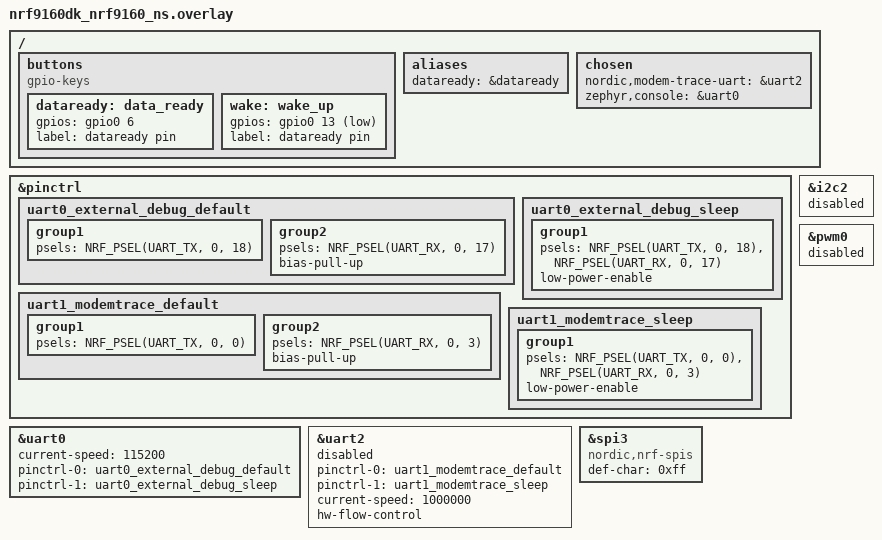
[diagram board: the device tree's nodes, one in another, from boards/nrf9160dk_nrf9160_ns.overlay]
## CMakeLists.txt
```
#
# Copyright (c) 2020 Nordic Semiconductor
#
# SPDX-License-Identifier: LicenseRef-Nordic-5-Clause
#

cmake_minimum_required(VERSION 3.20.0)

list(APPEND CONF_FILE prj.conf)

if (EXISTS prj.local.conf)
  list(APPEND CONF_FILE prj.local.conf)
endif()
if (CONFIG_RELEASE_BUILD)
  message("Doing a RELEASE build")
  list(APPEND CONF_FILE prj.release.conf)
endif()

find_package(Zephyr REQUIRED HINTS $ENV{ZEPHYR_BASE})
project(purina_d1_lte  VERSION 1.1.12)
zephyr_library_include_directories(src/include)




target_sources(app PRIVATE src/main.c)
target_sources(app PRIVATE src/wi.c)
target_sources(app PRIVATE src/status/status.c)
target_sources(app PRIVATE src/network/network.c)
target_sources(app PRIVATE src/zbus/zbus_msgs.c)
target_sources(app PRIVATE src/zbus/shutdown.c)
target_sources(app PRIVATE src/spi/spis_interface.c)
target_sources(app PRIVATE src/purina_iot/transport.c)
target_sources(app PRIVATE src/purina_iot/fota.c)
target_sources(app PRIVATE src/purina_iot/nrf91_upgrade.c)
add_subdirectory(src/gps)



zephyr_include_directories(src)
zephyr_include_directories(src/include)
zephyr_include_directories(src/spi)
zephyr_include_directories(src/zbus)
zephyr_include_directories(src/network)
zephyr_include_directories(src/status)
zephyr_include_directories(src/purina_iot)
zephyr_include_directories(../c_modules/modem/include)
zephyr_include_directories(src/gps)
target_include_directories(app PRIVATE ${ZEPHYR_BASE}/../nrf/ext/curl/include/)
target_include_directories(app PRIVATE ${ZEPHYR_BASE}/include/zephyr/posix/)
add_definitions(-DAPP_VERSION_MAJOR_CMAKE=${PROJECT_VERSION_MAJOR})
add_definitions(-DAPP_VERSION_MINOR_CMAKE=${PROJECT_VERSION_MINOR})
add_definitions(-DAPP_VERSION_PATCH_CMAKE=${PROJECT_VERSION_PATCH})



# Get the current Git commit hash
execute_process(
  COMMAND git rev-parse --short=6 HEAD
  WORKING_DIRECTORY ${CMAKE_SOURCE_DIR}
  OUTPUT_VARIABLE GIT_HASH
  OUTPUT_STRIP_TRAILING_WHITESPACE
)

# Check if the repository is dirty
execute_process(
  COMMAND git status --porcelain
  WORKING_DIRECTORY ${CMAKE_SOURCE_DIR}
  OUTPUT_VARIABLE GIT_DIRTY_STATUS
  OUTPUT_STRIP_TRAILING_WHITESPACE
)

# Append '-dirty' to the version string if the repository is dirty
if(NOT GIT_DIRTY_STATUS STREQUAL "")
  set(GIT_HASH "${GIT_HASH}-dirty")
endif()

add_definitions(-DGIT_HASH_CMAKE=\"${GIT_HASH}\")

# Get the build machine name
execute_process(
  COMMAND hostname
  OUTPUT_VARIABLE BUILD_MACHINE
  OUTPUT_STRIP_TRAILING_WHITESPACE
)

# Get the build date
string(TIMESTAMP BUILD_DATE "%Y-%m-%d %H:%M:%S")

# Pass the variables to the code
add_definitions(-DBUILD_MACHINE_CMAKE=\"${BUILD_MACHINE}\")
add_definitions(-DBUILD_DATE_CMAKE=\"${BUILD_DATE}\")
```

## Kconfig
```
#
# Copyright (c) 2020 Nordic Semiconductor ASA
#
# SPDX-License-Identifier: LicenseRef-Nordic-5-Clause
#

menu "Purina D1 LTE Settings"

config PURINA_D1_LTE_JSON_MESSAGE_SIZE_MAX
	int "Maximum size of JSON messages"
	default 5120
	help
	  Maximum size of JSON messages that are sent to AWS IoT.

config PURINA_D1_LTE_JSON_TOPIC_SIZE_MAX
	int "Maximum size of JSON topics"
	default 48
	help
	  Maximum size of JSON topics that are sent to AWS IoT.

config PURINA_D1_LTE_IOT_BROKER_HOST_NAME_SIZE_MAX
	int "Maximum size of AWS IoT broker host name"
	default 64
	help
	  Maximum size of AWS IoT broker host name.

config PURINA_D1_LTE_CLIENT_ID_SIZE_MAX
	int "Maximum size of client ID string"
	default 32
	help
	  Maximum size of string for client ID.

config PURINA_D1_LTE_CLIENT_MAX_SUBSCRIPTION_TOPICS
	int "Maximum num of subscription topics"
	default 10

config PURINA_D1_LTE_PUBLICATION_INTERVAL_SECONDS
	int "Interval in seconds that the app will publish uptime/info data"
	default 60
	help
	  Currently sends info to a topic $aws/things/{HW_id}/shadow/update/documents with things like versions, uptime, etc.

config PURINA_D1_LTE_CONNECTION_RETRY_TIMEOUT_SECONDS
	int "Number of seconds between each AWS IoT connection retry"
	default 30

config PURINA_D1_LTE_MQTT_RECONNECTION_TIMEOUT_SECONDS
	int "Reconnection timeout in seconds"
	default 10
	help
	  Time in between reconnection attempts to the MQTT broker.

config PURINA_D1_SPIS_LOG_LEVEL
	int "spi module log level"
	default 4

config PURINA_D1_SPIS_RX_BUFFER_SIZE
	int "spi module rx buffer size"
	default 5120
	help
	  The size of the SPI module's RX buffer. defaulted to 5120 to support Nick's 5k power testing.

config PURINA_D1_SPIS_TX_BUFFER_SIZE
	int "spi module tx buffer size"
	default 3072

config PURINA_D1_LTE_DOWNLOAD_URL_SIZE_MAX
	int "Maximum size of download URL"
	default 2096
	help
	  Maximum size of download URL.

config PURINA_D1_DISABLE_MODEM_ON_BOOT
	bool "pause the boot before the modem connects"
	default n

config PURINA_D1_REBOOT_ON_ERROR
	bool "reboot on error"
	default y

config PURINA_D1_LTE_LOG_LEVEL
	int "log level"
	default 4

config PURINA_D1_DOWNLOAD_SECURITY_TAG
	int "download security tag"
	default 123

config PURINA_D1_LTE_GNSS_SAMPLE_MODE_CONTINUOUS
	bool "GNSS sample mode continuous"
	default y

config PURINA_D1_LTE_CLIENT_ID_PREFIX
	string "Client ID prefix"
	default "dog-"

config PURINA_D1_LTE_PRINT_GPS_STATS
	bool "Print GPS stats"
	default n

config PURINA_D1_LTE_ENABLE_ZBUS_LOG_MESSAGES
	bool "Enable log messages sent over zbus then to the 5340 - using send_zbus_debug_info()"
	default y

config PURINA_D1_LTE_ZBUS_LOG_MESSAGE_LEVEL
	int "Zbus log message level - any message with a level less than or equal this will be sent over zbus"
	default 3

config GNSS_PRIORITY_ON_FIRST_FIX
	bool "GNSS priority on first fix"
	default y

config RELEASE_BUILD
    bool "Production Release"
    help
      Set to true to disable various developer features and to enable additonal security

config PURINA_D1_LTE_FOTA_CHUNK_SIZE_MAX
	int "Maximum size of FOTA chunk"
	default 1024
	help
	  Maximum size of FOTA chunk.

rsource "src/gps/Kconfig"

module = PURINA_D1_LTE
module-str = Purina D1 LTE
source "${ZEPHYR_BASE}/subsys/logging/Kconfig.template.log_config"

endmenu

menu "Zephyr Kernel"
source "Kconfig.zephyr"
endmenu
```

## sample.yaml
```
sample:
  name: Purina D1 LTE
tests:
  sample.net.aws_iot:
    tags: ci_build
    build_only: true
    build_on_all: true
    integration_platforms:
      - nrf9160dk_nrf9160_ns
    platform_allow:
      - nrf9160dk_nrf9160_ns
```

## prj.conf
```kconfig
#
# Copyright (c) 2020 Nordic Semiconductor ASA
#
# SPDX-License-Identifier: LicenseRef-Nordic-5-Clause
#

# General
CONFIG_LOG=y
CONFIG_LOG_BUFFER_SIZE=2048
CONFIG_HW_ID_LIBRARY=y
CONFIG_ASSERT=y
CONFIG_JSON_LIBRARY=y

# Heap and stacks
CONFIG_HEAP_MEM_POOL_SIZE=8192
CONFIG_MAIN_STACK_SIZE=4096
CONFIG_SYSTEM_WORKQUEUE_STACK_SIZE=4096

# Network
CONFIG_NETWORKING=y
CONFIG_NET_NATIVE=y
CONFIG_NET_IPV4=y
CONFIG_NET_CONNECTION_MANAGER=y

CONFIG_SMF=y
CONFIG_REBOOT=y

CONFIG_MQTT_HELPER=y
CONFIG_MQTT_HELPER_SEC_TAG=123
CONFIG_MODEM_KEY_MGMT=y 

CONFIG_MQTT_CLEAN_SESSION=y

# TLS
CONFIG_MQTT_LIB_TLS=y
CONFIG_MQTT_HELPER_PORT=8883
CONFIG_MQTT_KEEPALIVE=600
CONFIG_MQTT_HELPER_STACK_SIZE=4096

CONFIG_BOOTLOADER_MCUBOOT=y
CONFIG_MCUBOOT_IMG_MANAGER=y

CONFIG_SPI=n
CONFIG_NRFX_SPIS3=y

# Flash - Used in FOTA, settings and storage for P-GPS.
CONFIG_STREAM_FLASH=y
CONFIG_FLASH=y
CONFIG_FLASH_PAGE_LAYOUT=y
CONFIG_FLASH_MAP=y
CONFIG_FCB=y
CONFIG_SETTINGS=y
CONFIG_SETTINGS_FCB=y
CONFIG_MPU_ALLOW_FLASH_WRITE=y


# MCUBOOT
CONFIG_BOOTLOADER_MCUBOOT=y
CONFIG_IMG_MANAGER=y
CONFIG_MCUBOOT_IMG_MANAGER=y
CONFIG_IMG_ERASE_PROGRESSIVELY=y
CONFIG_SECURE_BOOT=y
CONFIG_BUILD_S1_VARIANT=y
CONFIG_PM_EXTERNAL_FLASH_MCUBOOT_SECONDARY=n

CONFIG_ZBUS=y
#CONFIG_ZBUS_RUNTIME_OBSERVERS=y

# # LTE Link Control
CONFIG_LTE_LINK_CONTROL=y
CONFIG_LTE_NETWORK_MODE_LTE_M_GPS=y
# Request eDRX from the network
CONFIG_LTE_EDRX_REQ=y
CONFIG_LTE_PSM_REQ=y
# PSM requested periodic TAU 1 hour, dafault is 00000011
CONFIG_LTE_PSM_REQ_RPTAU="10000010"
CONFIG_LTE_PSM_REQ_RAT="00001000"

# default is 1001
# 0100 is 61.44 seconds
# 0011 is 40.96 seconds
CONFIG_LTE_EDRX_REQ_VALUE_NBIOT="0100"
#default is 1001
CONFIG_LTE_EDRX_REQ_VALUE_LTE_M="0100"
CONFIG_LTE_PTW_VALUE_LTE_M="0011"
CONFIG_LTE_PTW_VALUE_NBIOT="0011"
CONFIG_LTE_LINK_CONTROL=y
CONFIG_PURINA_D1_LTE_GNSS_SAMPLE_MODE_CONTINUOUS=y

CONFIG_REBOOT=y
CONFIG_CJSON_LIB=y

CONFIG_MQTT_HELPER_PAYLOAD_BUFFER_LEN=3072

## debug/demo flags here
CONFIG_PURINA_D1_DISABLE_MODEM_ON_BOOT=n
CONFIG_PURINA_D1_REBOOT_ON_ERROR=n
CONFIG_PM_DEVICE=y
CONFIG_POWEROFF=y
CONFIG_MQTT_HELPER_LOG_LEVEL_DBG=y
CONFIG_NRF_MODEM_LIB_TRACE=n
CONFIG_PURINA_D1_LTE_LOG_LEVEL=4
# CONFIG_SHELL_CMD_BUFF_SIZE=255
# CONFIG_SHELL_CMDS_RESIZE=y
CONFIG_HTTP_PARSER=y
CONFIG_FOTA_DOWNLOAD_LOG_LEVEL_DBG=y
CONFIG_DFU_TARGET_MCUBOOT=y
CONFIG_DOWNLOAD_CLIENT=y
CONFIG_DOWNLOAD_CLIENT_STACK_SIZE=4096
CONFIG_DFU_TARGET=y
#debug
# CONFIG_MQTT_HELPER_STACK_SIZE=4096
# CONFIG_MAIN_STACK_SIZE=4096
# CONFIG_SYSTEM_WORKQUEUE_STACK_SIZE=2048

# handle te super long pre-signed FOTA urls
CONFIG_DOWNLOAD_CLIENT_MAX_FILENAME_SIZE=2048
CONFIG_DOWNLOAD_CLIENT_MAX_HOSTNAME_SIZE=256
CONFIG_FOTA_DOWNLOAD=y
CONFIG_FOTA_DOWNLOAD_FILE_NAME_LENGTH=2048
CONFIG_FOTA_DOWNLOAD_HOST_NAME_LENGTH=256
#CONFIG_MQTT_LOG_LEVEL_DBG=y

CONFIG_DK_LIBRARY=y
CONFIG_NET_TCP=y
CONFIG_MQTT_HELPER_RX_TX_BUFFER_SIZE=4096
CONFIG_FOTA_DOWNLOAD_PROGRESS_EVT=y

CONFIG_DEBUG_THREAD_INFO=y

# Enable nRF Cloud assistance for GNSS sample
CONFIG_PURINA_D1_LTE_ASSISTANCE_NRF_CLOUD=y

# P-GPS
CONFIG_NRF_CLOUD_PGPS=y
CONFIG_NRF_CLOUD_PGPS_REPLACEMENT_THRESHOLD=4

# Disable A-GNSS, comment this if you want to use both A-GNSS and P-GPS at the same time
#CONFIG_NRF_CLOUD_AGNSS=n


#CONFIG_SUPL_CLIENT_LIB=y

# Enable SUPL assistance for GNSS sample
CONFIG_PURINA_D1_LTE_ASSISTANCE_SUPL=n
# SUPL client library requires that the newlib C library is used
#CONFIG_NEWLIB_LIBC=y
#CONFIG_NEWLIB_LIBC_FLOAT_PRINTF=y
CONFIG_CBPRINTF_FP_SUPPORT=y

# LTE Link Control
CONFIG_LTE_LINK_CONTROL=y
CONFIG_LTE_NETWORK_MODE_LTE_M_GPS=y
# Request eDRX from the network



# CONFIG_PURINA_D1_LTE_ASSISTANCE_NRF_CLOUD=n
# Enable nRF Cloud assistance for GNSS sample
CONFIG_PURINA_D1_LTE_ASSISTANCE_NRF_CLOUD=y

# P-GPS
CONFIG_NRF_CLOUD_SEC_TAG=16842753
#CONFIG_NRF_CLOUD_CLIENT_ID_SRC_INTERNAL_UUID=y
CONFIG_NRF_CLOUD_CLIENT_ID_SRC_IMEI=y
CONFIG_PURINA_D1_LTE_CLIENT_ID_PREFIX="dog-"
CONFIG_NRF_CLOUD_REST=y
CONFIG_NRF_CLOUD_PGPS=n
CONFIG_NRF_CLOUD_PGPS_REPLACEMENT_THRESHOLD=4
CONFIG_GNSS_PRIORITY_ON_FIRST_FIX=y
#CONFIG_NRF_CLOUD_PGPS_NUM_PREDICTIONS=42 for one week default, 84 is the maximum value indicating two weeks. 
#CONFIG_NRF_CLOUD_AGPS_FILTERED=y  look into this

# Disable A-GNSS, comment this if you want to use both A-GNSS and P-GPS at the same time
# CONFIG_NRF_CLOUD_AGNSS=n
CONFIG_DATE_TIME=y
CONFIG_HEAP_MEM_POOL_SIZE=16384

CONFIG_PURINA_D1_LTE_PRINT_GPS_STATS=n
#CONFIG_MODEM_ANTENNA_GNSS_EXTERNAL=y
#CONFIG_MODEM_ANTENNA_AT_COEX0="AT\%XCOEX0=1,1,1570,1580"

##CONFIG_PURINA_D1_LTE_POWER_SAVING_HIGH
##CONFIG_PURINA_D1_LTE_POWER_SAVING_MODERATE
##CONFIG_MCUBOOT_UTIL_LOG_LEVEL_DBG=y
CONFIG_SERIAL=y
CONFIG_UART_CONSOLE=y
#CONFIG_RTT_CONSOLE=y
#CONFIG_USE_SEGGER_RTT=y
CONFIG_LOG=y
CONFIG_AT_MONITOR_HEAP_SIZE=1024
CONFIG_MCUBOOT_BUILD_STRATEGY_FROM_SOURCE=y


CONFIG_PURINA_D1_LTE_PRINT_GPS_STATS=n

CONFIG_PURINA_D1_LTE_LOW_ACCURACY=n
CONFIG_LTE_NETWORK_MODE_LTE_M_GPS=y
CONFIG_PURINA_D1_LTE_MODE_CONTINUOUS=y
CONFIG_PURINA_D1_LTE_MODE_PERIODIC=n
```

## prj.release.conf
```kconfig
CONFIG_RELEASE_BUILD=y
CONFIG_SERIAL=n
CONFIG_UART_CONSOLE=n
CONFIG_LOG_DEFAULT_LEVEL=0
CONFIG_ASSERT=n

CONFIG_MQTT_HELPER_LOG_LEVEL_OFF=y
CONFIG_FOTA_DOWNLOAD_LOG_LEVEL_OFF=y
CONFIG_PURINA_D1_LTE_LOG_LEVEL_OFF=y
```

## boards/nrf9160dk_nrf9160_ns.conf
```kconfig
#
# Copyright (c) 2023 Nordic Semiconductor ASA
#
# SPDX-License-Identifier: LicenseRef-Nordic-5-Clause
#

# Configuration file for nRF9160 DK
# This file is merged with prj.conf in the application folder, and options
# set here will take precedence if they are present in both files.

# General
CONFIG_HW_STACK_PROTECTION=y
CONFIG_HW_ID_LIBRARY_SOURCE_IMEI=y
CONFIG_PICOLIBC=y

# Modem related configurations
CONFIG_MODEM_INFO=y
CONFIG_AT_HOST_LIBRARY=y
CONFIG_NRF_MODEM_LIB_NET_IF_AUTO_START=n
CONFIG_NRF_MODEM_LIB_ON_FAULT_APPLICATION_SPECIFIC=y

# Modem trace
# CONFIG_NRF_MODEM_LIB_TRACE=y
# CONFIG_NRF_MODEM_LIB_TRACE_BACKEND_UART=y
# CONFIG_NRF_MODEM_LIB_TRACE_BACKEND_UART_ZEPHYR=y
# CONFIG_SERIAL=y
# CONFIG_UART_ASYNC_API=y
# CONFIG_UART_1_ASYNC=y
# CONFIG_UART_1_INTERRUPT_DRIVEN=n

# Disable Duplicate Address Detection (DAD)
# due to not being properly implemented for offloaded interfaces.
CONFIG_NET_IPV6_NBR_CACHE=n
CONFIG_NET_IPV6_MLD=n

# Zephyr NET Connection Manager and Connectivity layer.
CONFIG_NET_CONNECTION_MANAGER_MONITOR_STACK_SIZE=1024
CONFIG_LTE_CONNECTIVITY=y
CONFIG_LTE_CONNECTIVITY_AUTO_DOWN=n

# Bootloader and FOTA related configurations

# MCUBOOT
CONFIG_BOOTLOADER_MCUBOOT=y
CONFIG_MCUBOOT_IMG_MANAGER=y

# Image manager
CONFIG_IMG_MANAGER=y
CONFIG_STREAM_FLASH=y
CONFIG_FLASH_MAP=y
CONFIG_FLASH=y
CONFIG_IMG_ERASE_PROGRESSIVELY=y

# AWS FOTA
# CONFIG_AWS_FOTA=y
CONFIG_FOTA_DOWNLOAD=y
CONFIG_DFU_TARGET=y

# Download client (needed by AWS FOTA)
CONFIG_DOWNLOAD_CLIENT=y
CONFIG_DOWNLOAD_CLIENT_STACK_SIZE=4096
```

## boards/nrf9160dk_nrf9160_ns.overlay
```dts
/*
 * Copyright (c) 2023 Nordic Semiconductor ASA
 *
 * SPDX-License-Identifier: LicenseRef-Nordic-5-Clause
 */

/* Enable uart1 for tracing. */



// /* Enable uart1 for tracing. */
// &uart1 {
// 	status = "okay";
// 	current-speed = < 1000000 >;
// 	hw-flow-control;
// };

// / {
// 	chosen {
// 		nordic,modem-trace-uart = &uart1;
// 	};
// };
/ {
	buttons {
        compatible = "gpio-keys";
		dataready: data_ready {
			gpios = <&gpio0 6 (GPIO_PULL_DOWN | GPIO_ACTIVE_HIGH)>;
			label = "dataready pin";
		};
		wake: wake_up {
			gpios = <&gpio0 13 (GPIO_PULL_UP | GPIO_ACTIVE_LOW)>;
			label = "dataready pin";
		};
	};

	aliases {
		dataready = &dataready;
	};
};

&pinctrl {
	uart0_external_debug_default: uart0_external_debug_default {
			group1 {
					psels = <NRF_PSEL(UART_TX, 0, 18)>;
			};
			group2 {
					psels = <NRF_PSEL(UART_RX, 0, 17)>;
					bias-pull-up;
			};
			/delete-property/ hw-flow-control;
	};

	uart0_external_debug_sleep: uart0_external_debug_sleep {
			group1 {
					psels = <NRF_PSEL(UART_TX, 0, 18)>,
							<NRF_PSEL(UART_RX, 0, 17)>;
					low-power-enable;
					/delete-property/ hw-flow-control;
			};
	};

	uart1_modemtrace_default: uart1_modemtrace_default {
		group1 {
				psels = <NRF_PSEL(UART_TX, 0, 0)>;
		};
		group2 {
				psels = <NRF_PSEL(UART_RX, 0, 3)>;
				bias-pull-up;
		};
		/delete-property/ hw-flow-control;
	};

	uart1_modemtrace_sleep: uart1_modemtrace_sleep {
			group1 {
					psels = <NRF_PSEL(UART_TX, 0, 0)>,
							<NRF_PSEL(UART_RX, 0, 3)>;
					low-power-enable;
					/delete-property/ hw-flow-control;
			};
	};


};

/* AT command interface - set to  uart0_external_debug_default for external header pins or uart0_netapp_default */
&uart0 {
	status = "okay";
	current-speed = <115200>;
	pinctrl-0 = <&uart0_external_debug_default>;
	pinctrl-1 = <&uart0_external_debug_sleep>;
	pinctrl-names = "default", "sleep";
};

/* Enable uart1 for tracing. */
&uart2 {
	status = "disabled";
	pinctrl-0 = <&uart1_modemtrace_default>;
	pinctrl-1 = <&uart1_modemtrace_sleep>;
	current-speed = < 1000000 >;
	hw-flow-control;
};


&spi3 {
	compatible = "nordic,nrf-spis";
	def-char = <0xff>;
};

&i2c2 {
	status = "disabled";
};

&pwm0 {
	status = "disabled";
};

/ {
	chosen {
		nordic,modem-trace-uart = &uart2;
		zephyr,console = &uart0;
	};
};
```

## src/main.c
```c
/*
 * Copyright (c) 2020 Nordic Semiconductor ASA
 *
 * SPDX-License-Identifier: LicenseRef-Nordic-5-Clause
 */
#include "app_version.h"
#include <zephyr/kernel.h>
#include <zephyr/sys/reboot.h>
#include <zephyr/dfu/mcuboot.h>
#include <zephyr/logging/log.h>
#include <zephyr/logging/log_ctrl.h>
#include <hal/nrf_gpio.h>
#include <zephyr/sys/iterable_sections.h>
#include <zephyr/shell/shell.h>
#include <stdio.h>
#include <stdlib.h>
#include <hw_id.h>
#include <zephyr/pm/device.h>
#include "transport.h"
#include "zbus_msgs.h"
#include "status.h"
#include <zephyr/sys/heap_listener.h>

#include <hal/nrf_uarte.h>
#include "wi.h"

/* Register log module */
LOG_MODULE_REGISTER(purina_d1_lte, CONFIG_PURINA_D1_LTE_LOG_LEVEL);

#define CONSOLE DT_CHOSEN(zephyr_console)

bool disable_modem = true;

#ifdef CONFIG_SYS_HEAP_LISTENER

extern struct k_heap _system_heap;

#define N_HEAP_BLKS 256
struct heap_usage {
	void *ptr;
	size_t bytes;
} heap_usage[N_HEAP_BLKS];

void on_heap_alloc(uintptr_t heap_id, void *mem, size_t bytes)
{
	for (int i = 0; i < N_HEAP_BLKS; i++) {
		if (heap_usage[i].ptr == NULL) {
			heap_usage[i].ptr = mem;
			heap_usage[i].bytes = bytes;
			return;
		}
	}
	LOG_INF("Too many allocated blocks to track! alloc %zu at %p", bytes, mem);
}
HEAP_LISTENER_ALLOC_DEFINE(alloc_listener, HEAP_ID_FROM_POINTER(&_system_heap.heap), on_heap_alloc);

void on_heap_free(uintptr_t heap_id, void *mem, size_t bytes)
{
	for (int i = 0; i < N_HEAP_BLKS; i++) {
		if (heap_usage[i].ptr == mem) {
			heap_usage[i].ptr = NULL;
			heap_usage[i].bytes = 0;
			return;
		}
	}
	LOG_INF("Freeing unallocated mem @ %p", mem);
}
HEAP_LISTENER_FREE_DEFINE(free_listener, HEAP_ID_FROM_POINTER(&_system_heap.heap), on_heap_free);

void do_print_heap(const struct shell *sh, int argc, char **argv)
{
	for (int i = 0; i < N_HEAP_BLKS; i++) {
		if (heap_usage[i].ptr) {
			shell_print(sh, "Alloc %zu @ %p", heap_usage[i].bytes, heap_usage[i].ptr);
		}
	}
}
 SHELL_CMD_REGISTER(heap, NULL, "Print heap blocks in use", do_print_heap);
#endif


int main(void)
{
	LOG_INF("---- Nestle D1 LTE -  version %d.%d.%d (%s)", APP_VERSION_MAJOR,
                APP_VERSION_MINOR, APP_VERSION_PATCH, GIT_HASH);
    LOG_INF("---- Built on %s by %s\r\n\r\n", DBUILD_DATE, DBUILD_MACHINE);

	wr_init();

	/* Mark image as working to avoid reverting to the former image after a reboot. */
#if defined(CONFIG_BOOTLOADER_MCUBOOT)
    // TODO do all the self checks before you call this
	boot_write_img_confirmed();
#endif

#ifdef CONFIG_SYS_HEAP_LISTENER
	heap_listener_register(&alloc_listener);
	heap_listener_register(&free_listener);
#endif


	// nrf_gpio_cfg_input(DT_GPIO_PIN(DT_NODELABEL(wake), gpios), NRF_GPIO_PIN_PULLUP);
	// nrf_gpio_cfg_sense_set(DT_GPIO_PIN(DT_NODELABEL(wake), gpios), NRF_GPIO_PIN_SENSE_LOW);

	transport_init();

	return 0;
}


// TODOs
// X get/update RSSI periodically
// - get/update list of towers? (https://developer.nordicsemi.com/nRF_Connect_SDK/doc/1.6.1/nrf/samples/nrf9160/multicell_location/README.html#nrf9160-multicell-location)
// - gps position/num-sats
// X add - get version num to spi commands
// - handle message chunking
// X change subscribe topics to be passed from 5340
// X cleanup subscribe topics so its dynamic
// X can I call modem_info_init earlier?
// X lte connection attempts just stop after a while
// X in mqtt over the spi, currently 5340 is putting \0 at the end of both topic and message, working but ugly.
// X something evil lurks in getStatusTime in status.c
// - add a download from url -> send to 5340 function
// X force update of any status info to keep it fresh. and/or timestamp each of the items (gps, time, etc)
// X add send_5k for nick
// X combine the 3 places reboot/shutdown are called into one function
// X remove all device ID references and take one passed from 5340
// X remove all host/url/port and other connections from the code and take them from 5340
// X create telemetry module on 5340, takes in data/events and sends periodically

// at%XCOEX0=1,1,1570,1580     GNSS coexistance

// nrf9160 send_at AT+CFUN=0
// nrf9160 send_at AT\%XMIPIRFFEDEV?
// nrf9160 send_at AT\%XMIPIRFFEDEV=4,4,102,3,184
// nrf9160 send_at AT\%XMIPIRFFECTRL=4,0,1,28,184
// nrf9160 send_at AT\%XMIPIRFFECTRL=4,1,1,28,56,5,1,1,4,4,746,2,2,787,4,4,824,1,1,894,8,8,2200
// nrf9160 send_at AT\%XMIPIRFFECTRL=4,2,1,28,184
// nrf9160 send_at AT\%XMIPIRFFECTRL=4,3,1,28,184
// nrf9160 send_at AT+CFUN=0
```

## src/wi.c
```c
/*
 * This library implements a simple map of statically allocated k_work_item
 * structures.
 * Work items cannot by dynamically allocated, so this is used instead to allocate
 * and deallocate work items as needed.
 */

#include <zephyr/kernel.h>
#include <zephyr/logging/log.h>

#include "wi.h"
LOG_MODULE_REGISTER(wr, LOG_LEVEL_DBG);

#define MAX_WORK_ITEMS 128

static workref_t wrbuf[MAX_WORK_ITEMS];
static K_FIFO_DEFINE(wr_free_list);
static int  wrcount        = MAX_WORK_ITEMS;
static bool wr_initialized = false;

void wr_init(void)
{
    // mark all workrefs as free
    for (int i = 0; i < MAX_WORK_ITEMS; i++) {
        k_fifo_put(&wr_free_list, &wrbuf[i]);
    }
    wr_initialized = true;
}

// the following would all be better as static inline funcs in the header,
// except they need access to the freelist

workref_t *wr_get(void *ref, int line)
{
    if (!wr_initialized) {
        wr_init();
    }
    workref_t *wr = k_fifo_get(&wr_free_list, K_NO_WAIT);
    if (wr) {
        wr->reference = ref;
        wr->in_use    = line;
        wrcount--;
    } else {
        LOG_ERR("%s: No items on free list", __func__);
    }
    return wr;
}

void wr_put(workref_t *work)
{
    if (!wr_initialized) {
        wr_init();
    }
    work->in_use = 0;
    k_fifo_put(&wr_free_list, work);
    wrcount++;
}

void print_wr_stats()
{
    LOG_WRN("%d free workrefs", wrcount);
    for (int i = 0; i < MAX_WORK_ITEMS; i++) {
        if (wrbuf[i].in_use) {
            LOG_WRN("Index %d used for ref %p from line %d", i, wrbuf[i].reference, wrbuf[i].in_use);
        }
    }
}
```
